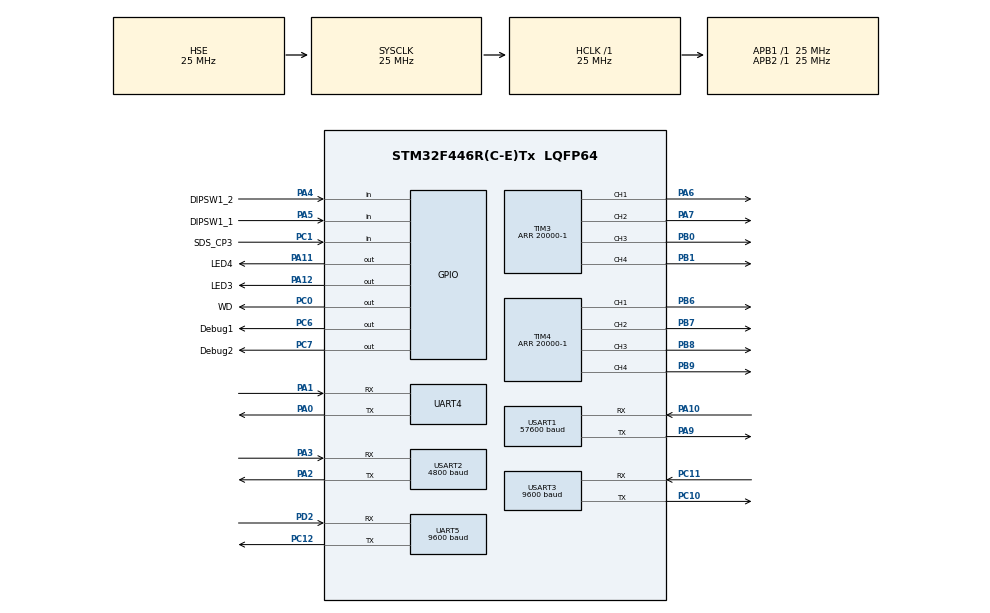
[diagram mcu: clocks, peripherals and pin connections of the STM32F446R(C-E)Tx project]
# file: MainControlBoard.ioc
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Mcu.Family=STM32F4
Mcu.Name=STM32F446R(C-E)Tx
Mcu.Package=LQFP64
NVIC.PriorityGroup=NVIC_PRIORITYGROUP_4
NVIC.TIM8_TRG_COM_TIM14_IRQn=true\:15\:0\:false\:false\:true\:false\:true\:true
NVIC.TimeBase=TIM8_TRG_COM_TIM14_IRQn
NVIC.TimeBaseIP=TIM14
NVIC.UART4_IRQn=true\:6\:0\:true\:false\:true\:true\:true\:true
NVIC.UART5_IRQn=true\:6\:0\:true\:false\:true\:true\:true\:true
NVIC.USART1_IRQn=true\:6\:0\:true\:false\:true\:true\:true\:true
NVIC.USART2_IRQn=true\:6\:0\:true\:false\:true\:true\:true\:true
NVIC.USART3_IRQn=true\:6\:0\:true\:false\:true\:true\:true\:true
PA0-WKUP.Mode=Asynchronous
PA0-WKUP.Signal=UART4_TX
PA1.Mode=Asynchronous
PA1.Signal=UART4_RX
PA10.Mode=Asynchronous
PA10.Signal=USART1_RX
PA11.GPIO_Label=LED4
PA11.GPIO_Speed=GPIO_SPEED_FREQ_LOW
PA11.Signal=GPIO_Output
PA12.GPIO_Label=LED3
PA12.Signal=GPIO_Output
PA2.Mode=Asynchronous
PA2.Signal=USART2_TX
PA3.Mode=Asynchronous
PA3.Signal=USART2_RX
PA4.GPIO_Label=DIPSW1_2
PA4.Signal=GPIO_Input
PA5.GPIO_Label=DIPSW1_1
PA5.Signal=GPIO_Input
PA6.Signal=S_TIM3_CH1
PA7.Signal=S_TIM3_CH2
PA9.Mode=Asynchronous
PA9.Signal=USART1_TX
PB0.Signal=S_TIM3_CH3
PB1.Signal=S_TIM3_CH4
PB6.Signal=S_TIM4_CH1
PB7.Signal=S_TIM4_CH2
PB8.Signal=S_TIM4_CH3
PB9.Signal=S_TIM4_CH4
PC0.GPIO_Label=WD
PC0.GPIO_ModeDefaultOutputPP=GPIO_MODE_OUTPUT_OD
PC0.GPIO_PuPd=GPIO_NOPULL
PC0.PinState=GPIO_PIN_SET
PC0.Signal=GPIO_Output
PC1.GPIO_Label=SDS_CP3
PC1.Signal=GPIO_Input
PC10.Mode=Asynchronous
PC10.Signal=USART3_TX
PC11.Mode=Asynchronous
PC11.Signal=USART3_RX
PC12.Mode=Asynchronous
PC12.Signal=UART5_TX
PC13.Mode=SYS_WakeUp1
PC13.Signal=SYS_WKUP1
PC6.GPIO_Label=Debug1
PC6.Signal=GPIO_Output
PC7.GPIO_Label=Debug2
PC7.PinState=GPIO_PIN_RESET
PC7.Signal=GPIO_Output
PD2.Mode=Asynchronous
PD2.Signal=UART5_RX
PH0-OSC_IN.Mode=HSE-External-Clock-Source
PH0-OSC_IN.Signal=RCC_OSC_IN
PH1-OSC_OUT.Mode=HSE-External-Clock-Source
PH1-OSC_OUT.Signal=RCC_OSC_OUT
ProjectManager.HeapSize=0x0
ProjectManager.StackSize=0x400
ProjectManager.TargetToolchain=STM32CubeIDE
RCC.AHBFreq_Value=25000000
RCC.APB1Freq_Value=25000000
RCC.APB1TimFreq_Value=25000000
RCC.APB2Freq_Value=25000000
RCC.APB2TimFreq_Value=25000000
RCC.CortexFreq_Value=25000000
RCC.HCLKFreq_Value=25000000
RCC.HSE_VALUE=25000000
RCC.PLLSourceVirtual=RCC_PLLSOURCE_HSE
RCC.SYSCLKFreq_VALUE=25000000
RCC.SYSCLKSource=RCC_SYSCLKSOURCE_HSE
RCC.USBFreq_Value=150000000
RCC.VCOOutputFreq_Value=300000000
SH.S_TIM3_CH1.0=TIM3_CH1,PWM Generation1 CH1
SH.S_TIM3_CH2.0=TIM3_CH2,PWM Generation2 CH2
SH.S_TIM3_CH3.0=TIM3_CH3,PWM Generation3 CH3
SH.S_TIM3_CH4.0=TIM3_CH4,PWM Generation4 CH4
SH.S_TIM4_CH1.0=TIM4_CH1,PWM Generation1 CH1
SH.S_TIM4_CH2.0=TIM4_CH2,PWM Generation2 CH2
SH.S_TIM4_CH3.0=TIM4_CH3,PWM Generation3 CH3
SH.S_TIM4_CH4.0=TIM4_CH4,PWM Generation4 CH4
TIM3.Channel-PWM\ Generation1\ CH1=TIM_CHANNEL_1
TIM3.Channel-PWM\ Generation2\ CH2=TIM_CHANNEL_2
TIM3.Channel-PWM\ Generation3\ CH3=TIM_CHANNEL_3
TIM3.Channel-PWM\ Generation4\ CH4=TIM_CHANNEL_4
TIM3.Period=20000-1
TIM3.Prescaler=25000000/1000000
TIM3.Pulse-PWM\ Generation1\ CH1=0
TIM3.Pulse-PWM\ Generation2\ CH2=0
TIM3.Pulse-PWM\ Generation3\ CH3=0
TIM3.Pulse-PWM\ Generation4\ CH4=0
TIM4.Channel-PWM\ Generation1\ CH1=TIM_CHANNEL_1
TIM4.Channel-PWM\ Generation2\ CH2=TIM_CHANNEL_2
TIM4.Channel-PWM\ Generation3\ CH3=TIM_CHANNEL_3
TIM4.Channel-PWM\ Generation4\ CH4=TIM_CHANNEL_4
TIM4.Period=20000-1
TIM4.Prescaler=25000000/1000000
TIM4.Pulse-PWM\ Generation1\ CH1=0
TIM4.Pulse-PWM\ Generation2\ CH2=0
TIM4.Pulse-PWM\ Generation3\ CH3=0
TIM4.Pulse-PWM\ Generation4\ CH4=0
UART4.VirtualMode=Asynchronous
UART5.BaudRate=9600
UART5.VirtualMode=Asynchronous
USART1.BaudRate=57600
USART1.VirtualMode=VM_ASYNC
USART2.BaudRate=4800
USART2.VirtualMode=VM_ASYNC
USART3.BaudRate=9600
USART3.VirtualMode=VM_ASYNC
VP_SYS_VS_tim14.Mode=TIM14
VP_TIM3_VS_ClockSourceINT.Mode=Internal
board=custom

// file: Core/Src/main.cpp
/* USER CODE BEGIN Header */
/**
 ******************************************************************************
 * @file           : main.cpp
 * @brief          : Main program body
 ******************************************************************************
 * @attention
 *
 * Copyright (c) 2022 STMicroelectronics.
 * All rights reserved.
 *
 * This software is licensed under terms that can be found in the LICENSE file
 * in the root directory of this software component.
 * If no LICENSE file comes with this software, it is provided AS-IS.
 *
 ******************************************************************************
 */
/* USER CODE END Header */
#include "main.h"
#include "tim.h"
#include "usart.h"
#include "gpio.h"

/* USER CODE BEGIN Includes */
#include <memory>

#include "UartInterrupt.h"
#include "HeartBeat.h"
#include "ExternalCommunication.h"
#include "CommandMgr.h"
#include "FreeRTOS.h"
#include "ExUartCommunication.h"
#include "Bms.h"
#include "DebugFunc.h"
#include "MainRoutine.h"
/* USER CODE END Includes */

void SystemClock_Config(void);

int main(void)
{

    /* MCU Configuration--------------------------------------------------------*/

    /* Reset of all peripherals, Initializes the Flash interface and the Systick. */
    HAL_Init();

    /* Configure the system clock */
    SystemClock_Config();

    /* Initialize all configured peripherals */
    MX_GPIO_Init();
    MX_USART2_UART_Init();
    MX_TIM3_Init();
    MX_TIM4_Init();
    MX_UART4_Init();
    MX_UART5_Init();
    MX_USART1_UART_Init();
    MX_USART3_UART_Init();
    /* USER CODE BEGIN 2 */

    auto main_rtn = std::make_unique<MainRoutine>();

    main_rtn->Init();
    main_rtn->StartRoutine();
    /* USER CODE END 2 */

    /* Infinite loop */
    while (1)
    {
        ;
    }
}

void SystemClock_Config(void)
{
    RCC_OscInitTypeDef RCC_OscInitStruct = {0};
    RCC_ClkInitTypeDef RCC_ClkInitStruct = {0};

    /** Configure the main internal regulator output voltage
     */
    __HAL_RCC_PWR_CLK_ENABLE();
    __HAL_PWR_VOLTAGESCALING_CONFIG(PWR_REGULATOR_VOLTAGE_SCALE3);

    /** Initializes the RCC Oscillators according to the specified parameters
     * in the RCC_OscInitTypeDef structure.
     */
    RCC_OscInitStruct.OscillatorType = RCC_OSCILLATORTYPE_HSE;
    RCC_OscInitStruct.HSEState = RCC_HSE_BYPASS;
    RCC_OscInitStruct.PLL.PLLState = RCC_PLL_NONE;
    if (HAL_RCC_OscConfig(&RCC_OscInitStruct) != HAL_OK)
    {
        Error_Handler();
    }

    /** Initializes the CPU, AHB and APB buses clocks
     */
    RCC_ClkInitStruct.ClockType = RCC_CLOCKTYPE_HCLK | RCC_CLOCKTYPE_SYSCLK | RCC_CLOCKTYPE_PCLK1 | RCC_CLOCKTYPE_PCLK2;
    RCC_ClkInitStruct.SYSCLKSource = RCC_SYSCLKSOURCE_HSE;
    RCC_ClkInitStruct.AHBCLKDivider = RCC_SYSCLK_DIV1;
    RCC_ClkInitStruct.APB1CLKDivider = RCC_HCLK_DIV1;
    RCC_ClkInitStruct.APB2CLKDivider = RCC_HCLK_DIV1;

    if (HAL_RCC_ClockConfig(&RCC_ClkInitStruct, FLASH_LATENCY_0) != HAL_OK)
    {
        Error_Handler();
    }
}

void HAL_TIM_PeriodElapsedCallback(TIM_HandleTypeDef *htim)
{
    if (htim->Instance == TIM14)
    {
        HAL_IncTick();
    }
}

void Error_Handler(void)
{
    __disable_irq();
    while (1)
    {
    }
}
